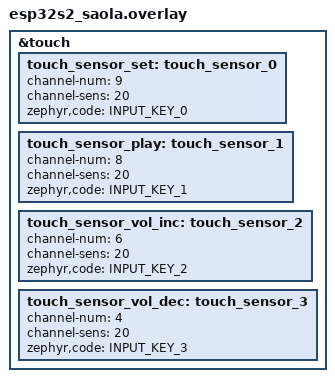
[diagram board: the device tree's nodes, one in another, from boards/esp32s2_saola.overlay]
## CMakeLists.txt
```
# SPDX-License-Identifier: Apache-2.0

cmake_minimum_required(VERSION 3.20.0)
find_package(Zephyr REQUIRED HINTS $ENV{ZEPHYR_BASE})
project(input_dump)

target_sources(app PRIVATE src/main.c)
```

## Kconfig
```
# Copyright 2023 Google LLC
# SPDX-License-Identifier: Apache-2.0

configdefault INPUT_SHELL
	default y

configdefault INPUT_SHELL_KBD_MATRIX_STATE
	default y

source "Kconfig.zephyr"
```

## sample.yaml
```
sample:
  name: Input Dump
common:
  tags: input
  build_only: true
  integration_platforms:
    - native_sim
tests:
  sample.input.input_dump: {}
  sample.input.input_dump_shell:
    extra_configs:
      - CONFIG_SHELL=y
```

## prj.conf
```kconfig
CONFIG_LOG=y
CONFIG_LOG_MODE_MINIMAL=y

CONFIG_INPUT=y
CONFIG_INPUT_EVENT_DUMP=y
```

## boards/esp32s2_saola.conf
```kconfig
CONFIG_INPUT_ESP32_TOUCH_SENSOR=y
```

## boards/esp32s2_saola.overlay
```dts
/*
 * Copyright (c) 2023 Espressif Systems (Shanghai) Co., Ltd.
 *
 * SPDX-License-Identifier: Apache-2.0
 */

#include <zephyr/dt-bindings/input/input-event-codes.h>
#include <zephyr/dt-bindings/input/esp32-touch-sensor-input.h>

&touch {
	status = "okay";

	touch_sensor_set: touch_sensor_0 {
		channel-num = <9>;
		channel-sens = <20>;
		zephyr,code = <INPUT_KEY_0>;
	};

	touch_sensor_play: touch_sensor_1 {
		channel-num = <8>;
		channel-sens = <20>;
		zephyr,code = <INPUT_KEY_1>;
	};

	touch_sensor_vol_inc: touch_sensor_2 {
		channel-num = <6>;
		channel-sens = <20>;
		zephyr,code = <INPUT_KEY_2>;
	};

	touch_sensor_vol_dec: touch_sensor_3 {
		channel-num = <4>;
		channel-sens = <20>;
		zephyr,code = <INPUT_KEY_3>;
	};
};
```

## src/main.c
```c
/*
 * Copyright 2023 Google LLC
 *
 * SPDX-License-Identifier: Apache-2.0
 */

#include <stdio.h>

int main(void)
{
	printf("Input sample started\n");
	return 0;
}
```
